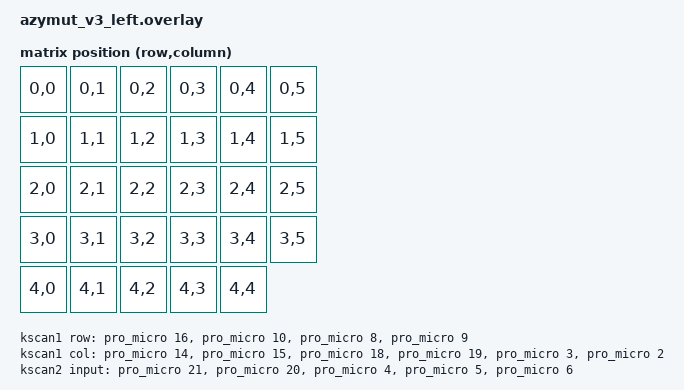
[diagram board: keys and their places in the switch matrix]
// This file was generated from a template. Edit it to match your keyboard.
// See https://zmk.dev/docs/development/hardware-integration/new-shield for more
// instructions.

/*
#include "azymut_v3.dtsi"

&kscan {
    // Replace these comments with the GPIO pins in the matrix for the left side.
    // See https://zmk.dev/docs/development/hardware-integration/new-shield#shield-overlays
    col-gpios
        = <&pro_micro 0 GPIO_ACTIVE_HIGH>
        , <&pro_micro 0 GPIO_ACTIVE_HIGH>
        ;
};
*/
#include "azymut_v3-layouts.dtsi"
#include "azymut_v3.dtsi"
#include <dt-bindings/zmk/matrix_transform.h>

#include <zephyr/dt-bindings/input/input-event-codes.h>


/ {
    chosen {
        zmk,kscan = &kscan0;
        zmk,analog-input = &anin0;
    };

    kscan0: kscan_composite {
        compatible = "zmk,kscan-composite";
        rows = <5>;
        columns = <6>;

        // Include the matrix driver
        matrix {
            kscan = <&kscan1>;
        };

        // Include the direct GPIO driver...
        direct {
            kscan = <&kscan2>;
            row-offset = <4>; // ...and shift it to not overlap
        };
    };

    kscan1: kscan_matrix {
        compatible = "zmk,kscan-gpio-matrix";
        diode-direction = "col2row";
        wakeup-source;

        // Replace these comments with the GPIO pins in the matrix.
        // See https://zmk.dev/docs/development/hardware-integration/new-shield#shield-overlays
        col-gpios
            = <&pro_micro 14 GPIO_ACTIVE_HIGH>
            , <&pro_micro 15 GPIO_ACTIVE_HIGH>
            , <&pro_micro 18 GPIO_ACTIVE_HIGH>
            , <&pro_micro 19 GPIO_ACTIVE_HIGH>
            , <&pro_micro 3 GPIO_ACTIVE_HIGH>
            , <&pro_micro 2 GPIO_ACTIVE_HIGH>
            ;

        row-gpios
            = <&pro_micro 16 (GPIO_ACTIVE_HIGH | GPIO_PULL_DOWN)>
            , <&pro_micro 10 (GPIO_ACTIVE_HIGH | GPIO_PULL_DOWN)>
            , <&pro_micro 8 (GPIO_ACTIVE_HIGH | GPIO_PULL_DOWN)>
            , <&pro_micro 9 (GPIO_ACTIVE_HIGH | GPIO_PULL_DOWN)>
            ;
        // define 3x3 matrix here...
    };

    kscan2: kscan_direct {
        compatible = "zmk,kscan-gpio-direct";
        wakeup-source;
        input-gpios
            = <&pro_micro 21 (GPIO_ACTIVE_LOW | GPIO_PULL_UP)>
            , <&pro_micro 20 (GPIO_ACTIVE_LOW | GPIO_PULL_UP)>
            , <&pro_micro 4 (GPIO_ACTIVE_LOW | GPIO_PULL_UP)>
            , <&pro_micro 5 (GPIO_ACTIVE_LOW | GPIO_PULL_UP)>
            , <&pro_micro 6 (GPIO_ACTIVE_LOW | GPIO_PULL_UP)>
            ;
        // define 2 direct GPIOs here...
    };

    anin0: analog_input_0 {
		compatible = "zmk,analog-input";
		sampling-hz = <100>;
		x-ch {
			io-channels = <&adc 31>; // <--- see ain-map.png for nRF52840
			mv-mid = <1630>;
			mv-min-max = <1600>;
			mv-deadzone = <10>;
			scale-multiplier = <1>;
			scale-divisor = <70>;
			invert;
			evt-type = <INPUT_EV_REL>;
			input-code = <INPUT_REL_X>;
		};
		y-ch {
			io-channels = <&adc 29>; // <--- see ain-map.png for nRF52840
			mv-mid = <1630>;
			mv-min-max = <1600>;
			mv-deadzone = <10>;
			scale-multiplier = <3>;
			scale-divisor = <4>;
			invert;
			evt-type = <INPUT_EV_REL>;
			input-code = <INPUT_REL_Y>;

			/* enable report mdoe for gamepad axix or knob */
			/* to only call input_report on quantquantized value is updated */
			/* NOTE: mouse input does NOT need this */
			report-on-change-only;

		};
	};



    default_transform: default_transform {
        // See https://zmk.dev/docs/development/hardware-integration/new-shield#matrix-transform
        // for how to configure this
        compatible = "zmk,matrix-transform";
        columns = <6>;
        rows = <5>;

        map = <
            RC(0, 0) RC(0, 1) RC(0, 2) RC(0, 3) RC(0, 4) RC(0, 5)
            RC(1, 0) RC(1, 1) RC(1, 2) RC(1, 3) RC(1, 4) RC(1, 5)
            RC(2, 0) RC(2, 1) RC(2, 2) RC(2, 3) RC(2, 4) RC(2, 5)
            RC(3, 0) RC(3, 1) RC(3, 2) RC(3, 3) RC(3, 4) RC(3, 5)
            RC(4, 0) RC(4, 1) RC(4, 2) RC(4, 3) RC(4, 4) //RC(4, 5)//
        >;
    };


};
